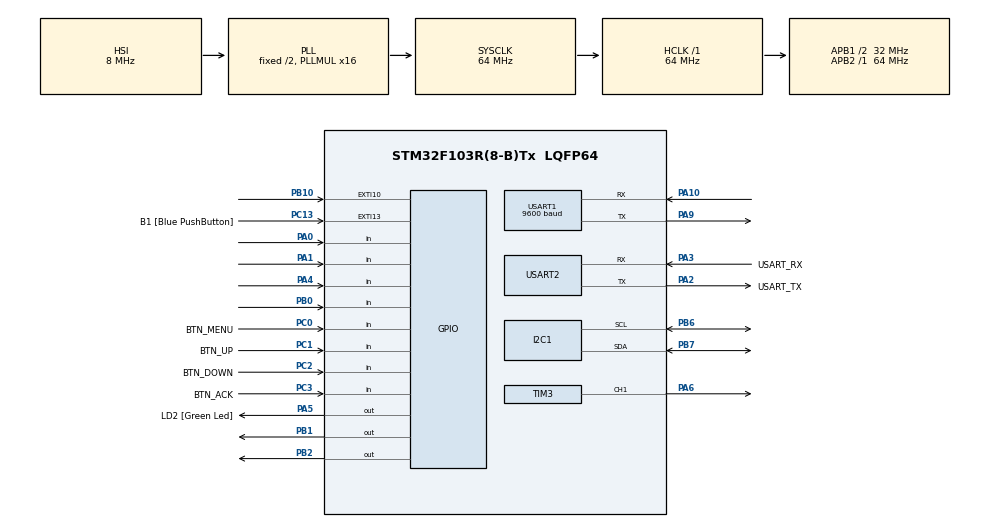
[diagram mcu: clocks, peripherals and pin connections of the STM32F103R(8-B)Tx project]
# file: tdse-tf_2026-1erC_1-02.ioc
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Dma.Request0=USART1_TX
Dma.USART1_TX.0.Direction=DMA_MEMORY_TO_PERIPH
Dma.USART1_TX.0.Instance=DMA1_Channel4
Dma.USART1_TX.0.MemDataAlignment=DMA_MDATAALIGN_BYTE
Dma.USART1_TX.0.MemInc=DMA_MINC_ENABLE
Dma.USART1_TX.0.Mode=DMA_NORMAL
Dma.USART1_TX.0.PeriphDataAlignment=DMA_PDATAALIGN_BYTE
Dma.USART1_TX.0.PeriphInc=DMA_PINC_DISABLE
Dma.USART1_TX.0.Priority=DMA_PRIORITY_LOW
I2C1.I2C_Mode=I2C_Fast
Mcu.Family=STM32F1
Mcu.Name=STM32F103R(8-B)Tx
Mcu.Package=LQFP64
NVIC.DMA1_Channel4_IRQn=true\:0\:0\:false\:false\:true\:false\:true\:true
NVIC.EXTI15_10_IRQn=true\:0\:0\:false\:false\:true\:true\:true\:true
NVIC.I2C1_ER_IRQn=true\:0\:0\:false\:false\:true\:true\:true\:true
NVIC.I2C1_EV_IRQn=true\:0\:0\:false\:false\:true\:true\:true\:true
NVIC.PriorityGroup=NVIC_PRIORITYGROUP_4
NVIC.USART1_IRQn=true\:0\:0\:false\:false\:true\:true\:true\:true
PA0-WKUP.Signal=GPIO_Input
PA1.Signal=GPIO_Input
PA10.Mode=Asynchronous
PA10.Signal=USART1_RX
PA13.GPIO_Label=TMS
PA13.Mode=Serial_Wire
PA13.Signal=SYS_JTMS-SWDIO
PA14.GPIO_Label=TCK
PA14.Mode=Serial_Wire
PA14.Signal=SYS_JTCK-SWCLK
PA2.GPIO_Label=USART_TX
PA2.GPIO_Mode=GPIO_MODE_AF_PP
PA2.GPIO_PuPd=GPIO_NOPULL
PA2.GPIO_Speed=GPIO_SPEED_FREQ_LOW
PA2.Mode=Asynchronous
PA2.Signal=USART2_TX
PA3.GPIO_Label=USART_RX
PA3.GPIO_Mode=GPIO_MODE_AF_PP
PA3.GPIO_PuPd=GPIO_NOPULL
PA3.GPIO_Speed=GPIO_SPEED_FREQ_LOW
PA3.Mode=Asynchronous
PA3.Signal=USART2_RX
PA4.Signal=GPIO_Input
PA5.GPIO_Label=LD2 [Green Led]
PA5.GPIO_ModeDefaultOutputPP=GPIO_MODE_OUTPUT_PP
PA5.GPIO_PuPd=GPIO_NOPULL
PA5.GPIO_Speed=GPIO_SPEED_FREQ_LOW
PA5.Signal=GPIO_Output
PA6.Signal=S_TIM3_CH1
PA9.Mode=Asynchronous
PA9.Signal=USART1_TX
PB0.Signal=GPIO_Input
PB1.Signal=GPIO_Output
PB10.Signal=GPXTI10
PB2.Signal=GPIO_Output
PB3.GPIO_Label=SWO
PB3.Signal=SYS_JTDO-TRACESWO
PB6.Mode=I2C
PB6.Signal=I2C1_SCL
PB7.Mode=I2C
PB7.Signal=I2C1_SDA
PC0.GPIO_Label=BTN_MENU
PC0.Signal=GPIO_Input
PC1.GPIO_Label=BTN_UP
PC1.Signal=GPIO_Input
PC13-TAMPER-RTC.GPIO_Label=B1 [Blue PushButton]
PC13-TAMPER-RTC.GPIO_PuPd=GPIO_NOPULL
PC13-TAMPER-RTC.Signal=GPXTI13
PC14-OSC32_IN.Mode=LSE-External-Oscillator
PC14-OSC32_IN.Signal=RCC_OSC32_IN
PC15-OSC32_OUT.Mode=LSE-External-Oscillator
PC15-OSC32_OUT.Signal=RCC_OSC32_OUT
PC2.GPIO_Label=BTN_DOWN
PC2.Signal=GPIO_Input
PC3.GPIO_Label=BTN_ACK
PC3.Signal=GPIO_Input
PD0-OSC_IN.Mode=HSE-External-Clock-Source
PD0-OSC_IN.Signal=RCC_OSC_IN
PD1-OSC_OUT.Mode=HSE-External-Clock-Source
PD1-OSC_OUT.Signal=RCC_OSC_OUT
ProjectManager.HeapSize=0x200
ProjectManager.StackSize=0x400
ProjectManager.TargetToolchain=STM32CubeIDE
RCC.AHBFreq_Value=64000000
RCC.APB1CLKDivider=RCC_HCLK_DIV2
RCC.APB1Freq_Value=32000000
RCC.APB1TimFreq_Value=64000000
RCC.APB2Freq_Value=64000000
RCC.APB2TimFreq_Value=64000000
RCC.HCLKFreq_Value=64000000
RCC.PLLMUL=RCC_PLL_MUL16
RCC.RTCClockSelection=RCC_RTCCLKSOURCE_LSE
RCC.SYSCLKFreq_VALUE=64000000
RCC.SYSCLKSource=RCC_SYSCLKSOURCE_PLLCLK
RCC.USBFreq_Value=64000000
SH.S_TIM3_CH1.0=TIM3_CH1,PWM Generation1 CH1
TIM3.Channel-PWM\ Generation1\ CH1=TIM_CHANNEL_1
USART1.BaudRate=9600
USART1.VirtualMode=VM_ASYNC
USART2.VirtualMode=VM_ASYNC
board=NUCLEO-F103RB

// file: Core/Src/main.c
/* USER CODE BEGIN Header */
/**
  ******************************************************************************
  * @file           : main.c
  * @brief          : Main program body
  ******************************************************************************
  * @attention
  *
  * Copyright (c) 2026 STMicroelectronics.
  * All rights reserved.
  *
  * This software is licensed under terms that can be found in the LICENSE file
  * in the root directory of this software component.
  * If no LICENSE file comes with this software, it is provided AS-IS.
  *
  ******************************************************************************
  */
/* USER CODE END Header */
#include "main.h"

/* USER CODE BEGIN Includes */

#include "logger.h"
#include "app.h"

/* USER CODE END Includes */

I2C_HandleTypeDef hi2c1;

TIM_HandleTypeDef htim3;

UART_HandleTypeDef huart1;
UART_HandleTypeDef huart2;
DMA_HandleTypeDef hdma_usart1_tx;

void SystemClock_Config(void);
static void MX_GPIO_Init(void);
static void MX_DMA_Init(void);
static void MX_USART2_UART_Init(void);
static void MX_I2C1_Init(void);
static void MX_TIM3_Init(void);
static void MX_USART1_UART_Init(void);

/* USER CODE BEGIN 0 */
#if (1 == LOGGER_CONFIG_USE_SEMIHOSTING)

extern void initialise_monitor_handles(void);

#endif

/* USER CODE END 0 */

int main(void)
{

  /* USER CODE BEGIN 1 */
  #if (1 == LOGGER_CONFIG_USE_SEMIHOSTING)

  initialise_monitor_handles();

  #endif

  /* USER CODE END 1 */

  /* MCU Configuration--------------------------------------------------------*/

  /* Reset of all peripherals, Initializes the Flash interface and the Systick. */
  HAL_Init();

  /* Configure the system clock */
  SystemClock_Config();

  /* Initialize all configured peripherals */
  MX_GPIO_Init();
  MX_DMA_Init();
  MX_USART2_UART_Init();
  MX_I2C1_Init();
  MX_TIM3_Init();
  MX_USART1_UART_Init();
  /* USER CODE BEGIN 2 */
  app_init();
  /* USER CODE END 2 */

  /* Infinite loop */
  while (1)
  {

    /* USER CODE BEGIN 3 */
    app_update();

    /* Bajo Consumo: Suspender el procesador hasta la proxima interrupcion (ej. SysTick) */
    __WFI();
  }
  /* USER CODE END 3 */
}

void SystemClock_Config(void)
{
  RCC_OscInitTypeDef RCC_OscInitStruct = {0};
  RCC_ClkInitTypeDef RCC_ClkInitStruct = {0};

  /** Initializes the RCC Oscillators according to the specified parameters
  * in the RCC_OscInitTypeDef structure.
  */
  RCC_OscInitStruct.OscillatorType = RCC_OSCILLATORTYPE_HSI;
  RCC_OscInitStruct.HSIState = RCC_HSI_ON;
  RCC_OscInitStruct.HSICalibrationValue = RCC_HSICALIBRATION_DEFAULT;
  RCC_OscInitStruct.PLL.PLLState = RCC_PLL_ON;
  RCC_OscInitStruct.PLL.PLLSource = RCC_PLLSOURCE_HSI_DIV2;
  RCC_OscInitStruct.PLL.PLLMUL = RCC_PLL_MUL16;
  if (HAL_RCC_OscConfig(&RCC_OscInitStruct) != HAL_OK)
  {
    Error_Handler();
  }

  /** Initializes the CPU, AHB and APB buses clocks
  */
  RCC_ClkInitStruct.ClockType = RCC_CLOCKTYPE_HCLK|RCC_CLOCKTYPE_SYSCLK
                              |RCC_CLOCKTYPE_PCLK1|RCC_CLOCKTYPE_PCLK2;
  RCC_ClkInitStruct.SYSCLKSource = RCC_SYSCLKSOURCE_PLLCLK;
  RCC_ClkInitStruct.AHBCLKDivider = RCC_SYSCLK_DIV1;
  RCC_ClkInitStruct.APB1CLKDivider = RCC_HCLK_DIV2;
  RCC_ClkInitStruct.APB2CLKDivider = RCC_HCLK_DIV1;

  if (HAL_RCC_ClockConfig(&RCC_ClkInitStruct, FLASH_LATENCY_2) != HAL_OK)
  {
    Error_Handler();
  }
}

static void MX_I2C1_Init(void)
{

  hi2c1.Instance = I2C1;
  hi2c1.Init.ClockSpeed = 400000;
  hi2c1.Init.DutyCycle = I2C_DUTYCYCLE_2;
  hi2c1.Init.OwnAddress1 = 0;
  hi2c1.Init.AddressingMode = I2C_ADDRESSINGMODE_7BIT;
  hi2c1.Init.DualAddressMode = I2C_DUALADDRESS_DISABLE;
  hi2c1.Init.OwnAddress2 = 0;
  hi2c1.Init.GeneralCallMode = I2C_GENERALCALL_DISABLE;
  hi2c1.Init.NoStretchMode = I2C_NOSTRETCH_DISABLE;
  if (HAL_I2C_Init(&hi2c1) != HAL_OK)
  {
    Error_Handler();
  }

}

static void MX_TIM3_Init(void)
{

  TIM_MasterConfigTypeDef sMasterConfig = {0};
  TIM_OC_InitTypeDef sConfigOC = {0};

  htim3.Instance = TIM3;
  htim3.Init.Prescaler = 0;
  htim3.Init.CounterMode = TIM_COUNTERMODE_UP;
  htim3.Init.Period = 65535;
  htim3.Init.ClockDivision = TIM_CLOCKDIVISION_DIV1;
  htim3.Init.AutoReloadPreload = TIM_AUTORELOAD_PRELOAD_DISABLE;
  if (HAL_TIM_PWM_Init(&htim3) != HAL_OK)
  {
    Error_Handler();
  }
  sMasterConfig.MasterOutputTrigger = TIM_TRGO_RESET;
  sMasterConfig.MasterSlaveMode = TIM_MASTERSLAVEMODE_DISABLE;
  if (HAL_TIMEx_MasterConfigSynchronization(&htim3, &sMasterConfig) != HAL_OK)
  {
    Error_Handler();
  }
  sConfigOC.OCMode = TIM_OCMODE_PWM1;
  sConfigOC.Pulse = 0;
  sConfigOC.OCPolarity = TIM_OCPOLARITY_HIGH;
  sConfigOC.OCFastMode = TIM_OCFAST_DISABLE;
  if (HAL_TIM_PWM_ConfigChannel(&htim3, &sConfigOC, TIM_CHANNEL_1) != HAL_OK)
  {
    Error_Handler();
  }
  HAL_TIM_MspPostInit(&htim3);

}

static void MX_USART1_UART_Init(void)
{

  huart1.Instance = USART1;
  huart1.Init.BaudRate = 9600;
  huart1.Init.WordLength = UART_WORDLENGTH_8B;
  huart1.Init.StopBits = UART_STOPBITS_1;
  huart1.Init.Parity = UART_PARITY_NONE;
  huart1.Init.Mode = UART_MODE_TX_RX;
  huart1.Init.HwFlowCtl = UART_HWCONTROL_NONE;
  huart1.Init.OverSampling = UART_OVERSAMPLING_16;
  if (HAL_UART_Init(&huart1) != HAL_OK)
  {
    Error_Handler();
  }

}

static void MX_USART2_UART_Init(void)
{

  huart2.Instance = USART2;
  huart2.Init.BaudRate = 115200;
  huart2.Init.WordLength = UART_WORDLENGTH_8B;
  huart2.Init.StopBits = UART_STOPBITS_1;
  huart2.Init.Parity = UART_PARITY_NONE;
  huart2.Init.Mode = UART_MODE_TX_RX;
  huart2.Init.HwFlowCtl = UART_HWCONTROL_NONE;
  huart2.Init.OverSampling = UART_OVERSAMPLING_16;
  if (HAL_UART_Init(&huart2) != HAL_OK)
  {
    Error_Handler();
  }

}

static void MX_DMA_Init(void)
{

  /* DMA controller clock enable */
  __HAL_RCC_DMA1_CLK_ENABLE();

  /* DMA interrupt init */
  /* DMA1_Channel4_IRQn interrupt configuration */
  HAL_NVIC_SetPriority(DMA1_Channel4_IRQn, 0, 0);
  HAL_NVIC_EnableIRQ(DMA1_Channel4_IRQn);

}

static void MX_GPIO_Init(void)
{
  GPIO_InitTypeDef GPIO_InitStruct = {0};

  /* GPIO Ports Clock Enable */
  __HAL_RCC_GPIOC_CLK_ENABLE();
  __HAL_RCC_GPIOD_CLK_ENABLE();
  __HAL_RCC_GPIOA_CLK_ENABLE();
  __HAL_RCC_GPIOB_CLK_ENABLE();

  /*Configure GPIO pin Output Level */
  HAL_GPIO_WritePin(LD2_GPIO_Port, LD2_Pin, GPIO_PIN_RESET);

  /*Configure GPIO pin Output Level */
  HAL_GPIO_WritePin(GPIOB, GPIO_PIN_1|GPIO_PIN_2, GPIO_PIN_RESET);

  /*Configure GPIO pin : B1_Pin */
  GPIO_InitStruct.Pin = B1_Pin;
  GPIO_InitStruct.Mode = GPIO_MODE_IT_RISING;
  GPIO_InitStruct.Pull = GPIO_NOPULL;
  HAL_GPIO_Init(B1_GPIO_Port, &GPIO_InitStruct);

  /*Configure GPIO pins : BTN_MENU_Pin BTN_UP_Pin BTN_DOWN_Pin BTN_ACK_Pin */
  GPIO_InitStruct.Pin = BTN_MENU_Pin|BTN_UP_Pin|BTN_DOWN_Pin|BTN_ACK_Pin;
  GPIO_InitStruct.Mode = GPIO_MODE_INPUT;
  GPIO_InitStruct.Pull = GPIO_NOPULL;
  HAL_GPIO_Init(GPIOC, &GPIO_InitStruct);

  /*Configure GPIO pins : PA0 PA1 PA4 */
  GPIO_InitStruct.Pin = GPIO_PIN_0|GPIO_PIN_1|GPIO_PIN_4;
  GPIO_InitStruct.Mode = GPIO_MODE_INPUT;
  GPIO_InitStruct.Pull = GPIO_NOPULL;
  HAL_GPIO_Init(GPIOA, &GPIO_InitStruct);

  /*Configure GPIO pin : LD2_Pin */
  GPIO_InitStruct.Pin = LD2_Pin;
  GPIO_InitStruct.Mode = GPIO_MODE_OUTPUT_PP;
  GPIO_InitStruct.Pull = GPIO_NOPULL;
  GPIO_InitStruct.Speed = GPIO_SPEED_FREQ_LOW;
  HAL_GPIO_Init(LD2_GPIO_Port, &GPIO_InitStruct);

  /*Configure GPIO pin : PB0 */
  GPIO_InitStruct.Pin = GPIO_PIN_0;
  GPIO_InitStruct.Mode = GPIO_MODE_INPUT;
  GPIO_InitStruct.Pull = GPIO_NOPULL;
  HAL_GPIO_Init(GPIOB, &GPIO_InitStruct);

  /*Configure GPIO pins : PB1 PB2 */
  GPIO_InitStruct.Pin = GPIO_PIN_1|GPIO_PIN_2;
  GPIO_InitStruct.Mode = GPIO_MODE_OUTPUT_PP;
  GPIO_InitStruct.Pull = GPIO_NOPULL;
  GPIO_InitStruct.Speed = GPIO_SPEED_FREQ_LOW;
  HAL_GPIO_Init(GPIOB, &GPIO_InitStruct);

  /*Configure GPIO pin : PB10 */
  GPIO_InitStruct.Pin = GPIO_PIN_10;
  GPIO_InitStruct.Mode = GPIO_MODE_IT_RISING;
  GPIO_InitStruct.Pull = GPIO_NOPULL;
  HAL_GPIO_Init(GPIOB, &GPIO_InitStruct);

  /* EXTI interrupt init*/
  HAL_NVIC_SetPriority(EXTI15_10_IRQn, 0, 0);
  HAL_NVIC_EnableIRQ(EXTI15_10_IRQn);

}

void Error_Handler(void)
{
  __disable_irq();
  while (1)
  {
  }
}
